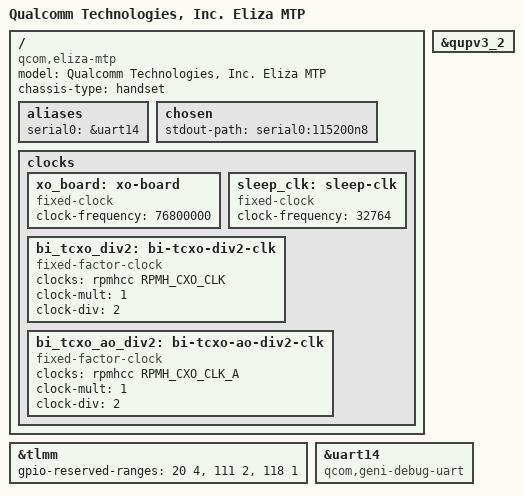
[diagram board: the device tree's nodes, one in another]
// SPDX-License-Identifier: BSD-3-Clause
/*
 * Copyright (c) 2022, Linaro Limited
 */

/dts-v1/;

#include <dt-bindings/regulator/qcom,rpmh-regulator.h>
#include "eliza.dtsi"

/ {
	model = "Qualcomm Technologies, Inc. Eliza MTP";
	compatible = "qcom,eliza-mtp", "qcom,eliza";
	chassis-type = "handset";

	aliases {
		serial0 = &uart14;
	};

	chosen {
		stdout-path = "serial0:115200n8";
	};

	clocks {
		xo_board: xo-board {
			compatible = "fixed-clock";
			clock-frequency = <76800000>;
			#clock-cells = <0>;
		};

		sleep_clk: sleep-clk {
			compatible = "fixed-clock";
		        clock-frequency = <32764>;
			#clock-cells = <0>;
		};

		bi_tcxo_div2: bi-tcxo-div2-clk {
			compatible = "fixed-factor-clock";
			#clock-cells = <0>;

			clocks = <&rpmhcc RPMH_CXO_CLK>;
			clock-mult = <1>;
			clock-div = <2>;
		};

		bi_tcxo_ao_div2: bi-tcxo-ao-div2-clk {
			compatible = "fixed-factor-clock";
			#clock-cells = <0>;

			clocks = <&rpmhcc RPMH_CXO_CLK_A>;
			clock-mult = <1>;
			clock-div = <2>;
		};
	};
};

&qupv3_2 {
	status = "okay";
};

&tlmm {
	/* reserved for secure world */
	gpio-reserved-ranges = <20 4>, <111 2>, <118 1>;
};

&uart14 {
	compatible = "qcom,geni-debug-uart";
	status = "okay";
};
